AUTOSAR XML (schema 00046)
package /McInt/SwComponents
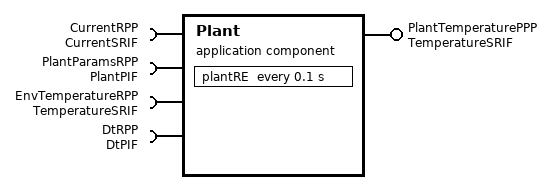
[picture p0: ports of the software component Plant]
  application sw component type Plant
    require port CurrentRPP: required-interface=CurrentSRIF  # Port to receive the current from the controller
    provide port PlantTemperaturePPP: provided-interface=TemperatureSRIF  # Port for sending out the estimated temperature of the plant
    require port PlantParamsRPP: required-interface=PlantPIF  # Port to get the parameters for the plant
    require port EnvTemperatureRPP: required-interface=TemperatureSRIF  # Port to receive the tempertature of the environment
    require port DtRPP: required-interface=DtPIF  # Port to get delta t, i.e. time of one time step
    behavior PlantInternalBehavior: data-type-mapping=DataTypeMappingSet, handle-termination-and-restart=NO-SUPPORT
      ar-typed-per-instance-memorys:
        data QHeater: sw-addr-method=VAR, sw-calibration-access=READ-ONLY, type=Energy  # Measurement point for heat flow between the electrical heater and the plant in the current time step.
        data QEnv: sw-addr-method=CODE, sw-calibration-access=READ-ONLY, type=Energy  # Measurement point for heat flow between the plant and the environment in the current time step.
      timing event plant100ms: start-on-event=plantRE, period=0.1
      implicit-inter-runnable-variables:
        data QPlant: sw-addr-method=CODE, sw-calibration-access=READ-ONLY, type=Energy, init-value=300 Joule  # Internal state of the plant: the stored eneregy quantity in the current time step
      runnable plantRE: sw-addr-method=CODE, symbol=plantRE_func
        data-read-access:
          access DRA_Current: accessed-variable=CurrentRPP.I
          access DRA_EnvTemperature: accessed-variable=EnvTemperatureRPP.T
        data-write-access:
          access DWA_PlantTemperature: accessed-variable=PlantTemperaturePPP.T
        parameter access PA_EnvFactor: accessed-parameter=PlantParamsRPP.plnt_EnvFactor
        parameter access PA_HeaterFactor: accessed-parameter=PlantParamsRPP.plnt_HeaterFactor
        parameter access PA_Dt: accessed-parameter=DtRPP.Dt
        read-local-variables:
          access ReadLocalVariables_QPlant: accessed-variable=QPlant
        written-local-variables:
          access WrittenLocalVariables_QPlant: accessed-variable=QPlant
